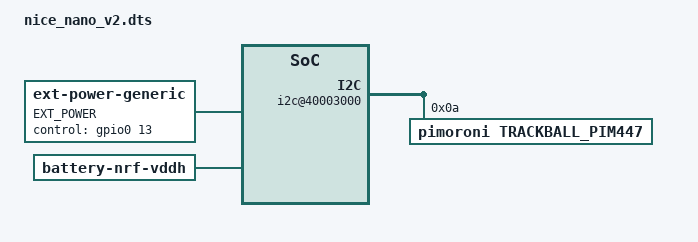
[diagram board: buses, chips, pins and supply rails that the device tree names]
/*
 * Copyright (c) 2021 The ZMK Contributors
 *
 * SPDX-License-Identifier: MIT
 */

/dts-v1/;
#include "nice_nano.dtsi"

/ {
	ext-power {
		compatible = "zmk,ext-power-generic";
		label = "EXT_POWER";
		control-gpios = <&gpio0 13 GPIO_ACTIVE_HIGH>;
		init-delay-ms = <10>;
	};

	vbatt {
		compatible = "zmk,battery-nrf-vddh";
		label = "BATTERY";
	};
      soc {
        i2c@40003000 {
            trackball_pim447@a {
                compatible = "pimoroni,trackball_pim447";
                reg = <0xa>; // 장치의 주소에 따라 수정 필요
                label = "TRACKBALL_PIM447";
                move-factor = <2>;
                invert-move-x;
                invert-move-y;
                button = <1>; // 필요한 버튼 설정
                swap-axes;
                scroll-divisor = <1>;
                invert-scroll-x;
                invert-scroll-y;
                mode = <2>; // 모드 설정 (옵션)
            };
        };
    };
};
